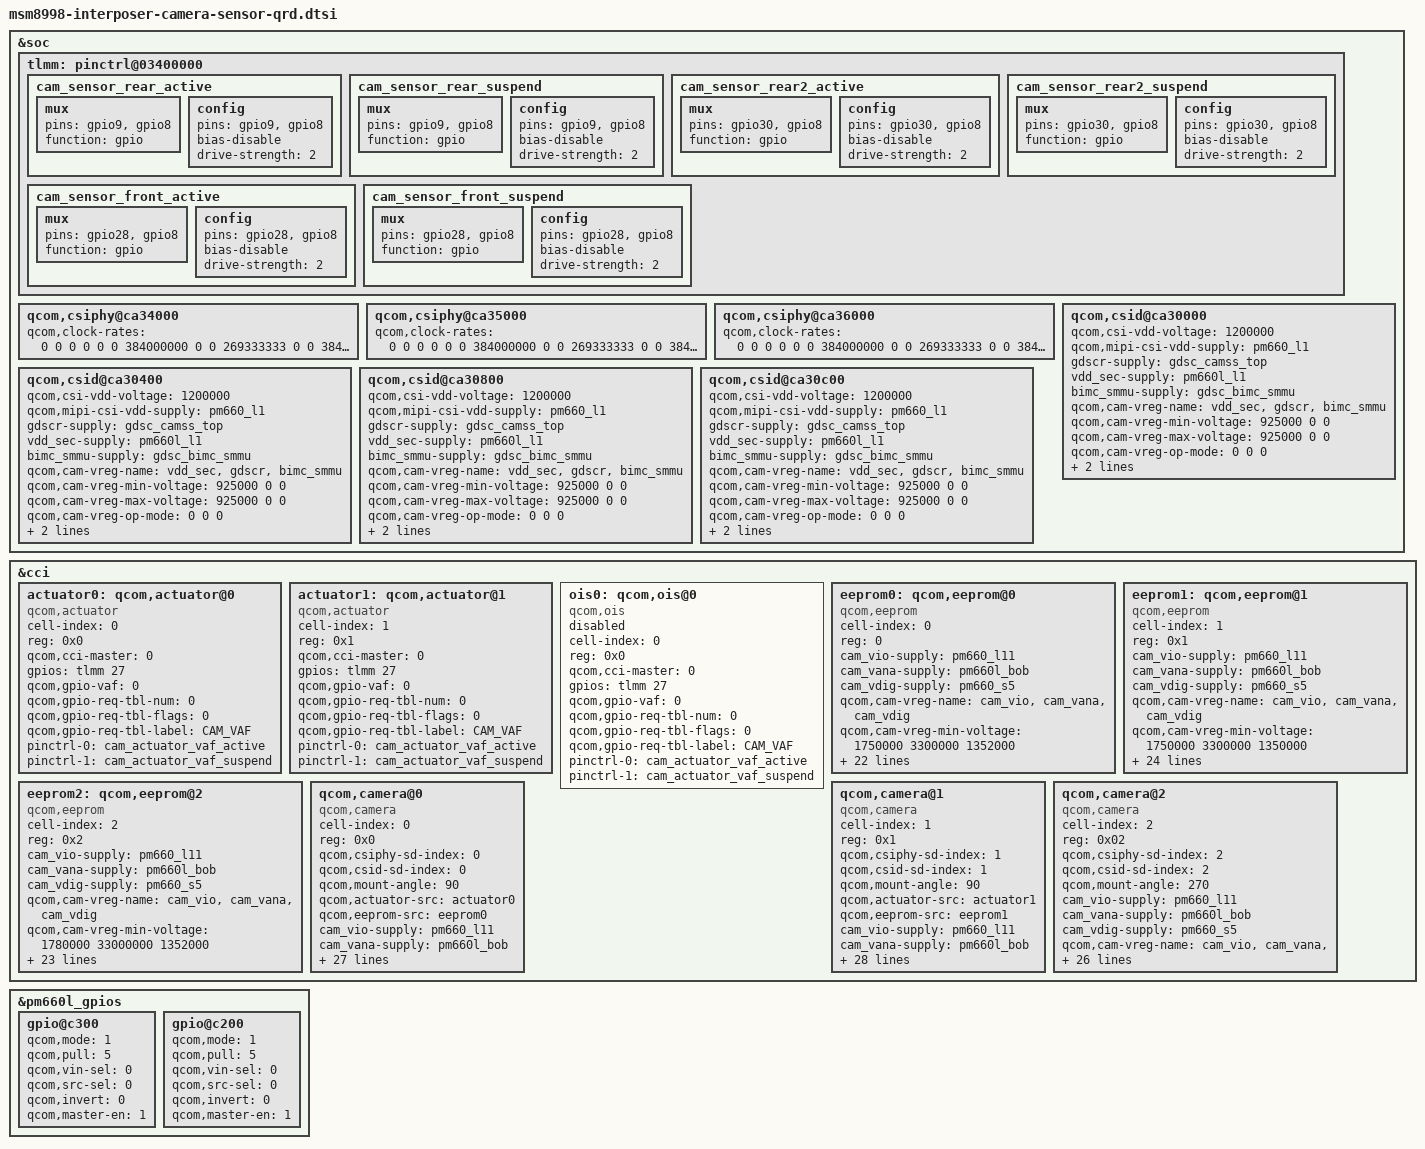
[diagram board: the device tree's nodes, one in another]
/*
 * Copyright (c) 2016-2017, The Linux Foundation. All rights reserved.
 *
 * This program is free software; you can redistribute it and/or modify
 * it under the terms of the GNU General Public License version 2 and
 * only version 2 as published by the Free Software Foundation.
 *
 * This program is distributed in the hope that it will be useful,
 * but WITHOUT ANY WARRANTY; without even the implied warranty of
 * MERCHANTABILITY or FITNESS FOR A PARTICULAR PURPOSE.  See the
 * GNU General Public License for more details.
 */

&soc {
	tlmm: pinctrl@03400000 {
		cam_sensor_rear_active: cam_sensor_rear_active {
			/* RESET, STANDBY */
			mux {
				pins = "gpio9", "gpio8";
				function = "gpio";
			};

			config {
				pins = "gpio9", "gpio8";
				bias-disable; /* No PULL */
				drive-strength = <2>; /* 2 MA */
			};
		};

		cam_sensor_rear_suspend: cam_sensor_rear_suspend {
			/* RESET, STANDBY */
			mux {
				pins = "gpio9", "gpio8";
				function = "gpio";
			};

			config {
				pins = "gpio9", "gpio8";
				bias-disable; /* No PULL */
				drive-strength = <2>; /* 2 MA */
			};
		};

		cam_sensor_rear2_active: cam_sensor_rear2_active {
			/* RESET, STANDBY */
			mux {
				pins = "gpio30", "gpio8";
				function = "gpio";
			};

			config {
				pins = "gpio30", "gpio8";
				bias-disable; /* No PULL */
				drive-strength = <2>; /* 2 MA */
			};
		};

		cam_sensor_rear2_suspend: cam_sensor_rear2_suspend {
			/* RESET, STANDBY */
			mux {
				pins = "gpio30", "gpio8";
				function = "gpio";
			};

			config {
				pins = "gpio30", "gpio8";
				bias-disable; /* No PULL */
				drive-strength = <2>; /* 2 MA */
			};
		};

		cam_sensor_front_active: cam_sensor_front_active {
			/* RESET */
			mux {
				pins = "gpio28","gpio8";
				function = "gpio";
			};

			config {
				pins = "gpio28","gpio8";
				bias-disable; /* No PULL */
				drive-strength = <2>; /* 2 MA */
			};
		};
		cam_sensor_front_suspend: cam_sensor_front_suspend {
			/* RESET */
			mux {
				pins = "gpio28","gpio8";
				function = "gpio";
			};

			config {
				pins = "gpio28","gpio8";
				bias-disable; /* No PULL */
				drive-strength = <2>; /* 2 MA */
			};
		};

	};

	qcom,csiphy@ca34000 {
		qcom,clock-rates = <0 0 0 0 0 0 384000000 0 0 269333333 0
			0 384000000 0>;
	};

	qcom,csiphy@ca35000 {
		qcom,clock-rates = <0 0 0 0 0 0 384000000 0 0 269333333 0
			0 384000000 0>;
	};

	qcom,csiphy@ca36000 {
		qcom,clock-rates = <0 0 0 0 0 0 384000000 0 0 269333333 0
			0 384000000 0>;
	};

	qcom,csid@ca30000  {
		qcom,csi-vdd-voltage = <1200000>;
		qcom,mipi-csi-vdd-supply = <&pm660_l1>;
		gdscr-supply = <&gdsc_camss_top>;
		vdd_sec-supply = <&pm660l_l1>;
		bimc_smmu-supply = <&gdsc_bimc_smmu>;
		qcom,cam-vreg-name = "vdd_sec", "gdscr", "bimc_smmu";
		qcom,cam-vreg-min-voltage = <925000 0 0>;
		qcom,cam-vreg-max-voltage = <925000 0 0>;
		qcom,cam-vreg-op-mode = <0 0 0>;
		qcom,clock-rates = <0 0 0 0 0 0 0 384000000 384000000
			0 0 0 0 0>;
	};

	qcom,csid@ca30400 {
		qcom,csi-vdd-voltage = <1200000>;
		qcom,mipi-csi-vdd-supply = <&pm660_l1>;
		gdscr-supply = <&gdsc_camss_top>;
		vdd_sec-supply = <&pm660l_l1>;
		bimc_smmu-supply = <&gdsc_bimc_smmu>;
		qcom,cam-vreg-name = "vdd_sec", "gdscr", "bimc_smmu";
		qcom,cam-vreg-min-voltage = <925000 0 0>;
		qcom,cam-vreg-max-voltage = <925000 0 0>;
		qcom,cam-vreg-op-mode = <0 0 0>;
		qcom,clock-rates = <0 0 0 0 0 0 0 384000000 384000000
			0 0 0 0 0>;
	};

	qcom,csid@ca30800 {
		qcom,csi-vdd-voltage = <1200000>;
		qcom,mipi-csi-vdd-supply = <&pm660_l1>;
		gdscr-supply = <&gdsc_camss_top>;
		vdd_sec-supply = <&pm660l_l1>;
		bimc_smmu-supply = <&gdsc_bimc_smmu>;
		qcom,cam-vreg-name = "vdd_sec", "gdscr", "bimc_smmu";
		qcom,cam-vreg-min-voltage = <925000 0 0>;
		qcom,cam-vreg-max-voltage = <925000 0 0>;
		qcom,cam-vreg-op-mode = <0 0 0>;
		qcom,clock-rates = <0 0 0 0 0 0 0 384000000 384000000
			0 0 0 0 0>;
	};

	qcom,csid@ca30c00 {
		qcom,csi-vdd-voltage = <1200000>;
		qcom,mipi-csi-vdd-supply = <&pm660_l1>;
		gdscr-supply = <&gdsc_camss_top>;
		vdd_sec-supply = <&pm660l_l1>;
		bimc_smmu-supply = <&gdsc_bimc_smmu>;
		qcom,cam-vreg-name = "vdd_sec", "gdscr", "bimc_smmu";
		qcom,cam-vreg-min-voltage = <925000 0 0>;
		qcom,cam-vreg-max-voltage = <925000 0 0>;
		qcom,cam-vreg-op-mode = <0 0 0>;
		qcom,clock-rates = <0 0 0 0 0 0 0 384000000 384000000
			0 0 0 0 0>;
	};
};

&soc {
	/delete-node/gpio-regulator@0;
};

&cci {
	/delete-node/qcom,camera@0;
	/delete-node/qcom,camera@1;
	/delete-node/qcom,camera@2;
	/delete-node/qcom,eeprom@0;
	/delete-node/qcom,eeprom@1;
	/delete-node/qcom,eeprom@2;
	/delete-node/qcom,actuator@0;
	/delete-node/qcom,actuator@1;
	/delete-node/qcom,ois@0;
};

&cci {
	actuator0: qcom,actuator@0 {
		cell-index = <0>;
		reg = <0x0>;
		compatible = "qcom,actuator";
		qcom,cci-master = <0>;
		gpios = <&tlmm 27 0>;
		qcom,gpio-vaf = <0>;
		qcom,gpio-req-tbl-num = <0>;
		qcom,gpio-req-tbl-flags = <0>;
		qcom,gpio-req-tbl-label = "CAM_VAF";
		pinctrl-names = "cam_default", "cam_suspend";
		pinctrl-0 = <&cam_actuator_vaf_active>;
		pinctrl-1 = <&cam_actuator_vaf_suspend>;
	};

	actuator1: qcom,actuator@1 {
		cell-index = <1>;
		reg = <0x1>;
		compatible = "qcom,actuator";
		qcom,cci-master = <0>;
		gpios = <&tlmm 27 0>;
		qcom,gpio-vaf = <0>;
		qcom,gpio-req-tbl-num = <0>;
		qcom,gpio-req-tbl-flags = <0>;
		qcom,gpio-req-tbl-label = "CAM_VAF";
		pinctrl-names = "cam_default", "cam_suspend";
		pinctrl-0 = <&cam_actuator_vaf_active>;
		pinctrl-1 = <&cam_actuator_vaf_suspend>;
	};

	ois0: qcom,ois@0 {
		cell-index = <0>;
		reg = <0x0>;
		compatible = "qcom,ois";
		qcom,cci-master = <0>;
		gpios = <&tlmm 27 0>;
		qcom,gpio-vaf = <0>;
		qcom,gpio-req-tbl-num = <0>;
		qcom,gpio-req-tbl-flags = <0>;
		qcom,gpio-req-tbl-label = "CAM_VAF";
		pinctrl-names = "cam_default", "cam_suspend";
		pinctrl-0 = <&cam_actuator_vaf_active>;
		pinctrl-1 = <&cam_actuator_vaf_suspend>;
		status = "disabled";
	};

	eeprom0: qcom,eeprom@0 {
		cell-index = <0>;
		reg = <0>;
		compatible = "qcom,eeprom";
		cam_vio-supply = <&pm660_l11>;
		cam_vana-supply = <&pm660l_bob>;
		cam_vdig-supply = <&pm660_s5>;
		qcom,cam-vreg-name = "cam_vio", "cam_vana", "cam_vdig";
		qcom,cam-vreg-min-voltage = <1750000 3300000 1352000>;
		qcom,cam-vreg-max-voltage = <1980000 3600000 1352000>;
		qcom,cam-vreg-op-mode = <105000 80000 105000>;
		qcom,gpio-no-mux = <0>;
		pinctrl-names = "cam_default", "cam_suspend";
		pinctrl-0 = <&cam_sensor_mclk0_active
				&cam_sensor_rear_active>;
		pinctrl-1 = <&cam_sensor_mclk0_suspend
				&cam_sensor_rear_suspend>;
		gpios = <&tlmm 13 0>,
			<&tlmm 9 0>,
			<&pm660l_gpios 4 0>,
			<&tlmm 8 0>;
		qcom,gpio-reset = <1>;
		qcom,gpio-vdig = <2>;
		qcom,gpio-vana = <3>;
		qcom,gpio-req-tbl-num = <0 1 2 3>;
		qcom,gpio-req-tbl-flags = <1 0 0 0>;
		qcom,gpio-req-tbl-label = "CAMIF_MCLK0",
					"CAM_RESET0",
					"CAM_VDIG",
					"CAM_VANA";
		qcom,sensor-position = <0>;
		qcom,sensor-mode = <0>;
		qcom,cci-master = <0>;
		status = "ok";
		clocks = <&clock_mmss clk_mclk0_clk_src>,
				<&clock_mmss clk_mmss_camss_mclk0_clk>;
		clock-names = "cam_src_clk", "cam_clk";
		qcom,clock-rates = <24000000 0>;
	};

	eeprom1: qcom,eeprom@1 {
		cell-index = <1>;
		reg = <0x1>;
		compatible = "qcom,eeprom";
		cam_vio-supply = <&pm660_l11>;
		cam_vana-supply = <&pm660l_bob>;
		cam_vdig-supply = <&pm660_s5>;
		qcom,cam-vreg-name = "cam_vio", "cam_vana", "cam_vdig";
		qcom,cam-vreg-min-voltage = <1750000 3300000 1350000>;
		qcom,cam-vreg-max-voltage = <1980000 3600000 1350000>;
		qcom,cam-vreg-op-mode = <105000 80000 105000>;
		qcom,gpio-no-mux = <0>;
		pinctrl-names = "cam_default", "cam_suspend";
		pinctrl-0 = <&cam_sensor_mclk2_active
				 &cam_sensor_rear2_active>;
		pinctrl-1 = <&cam_sensor_mclk2_suspend
				 &cam_sensor_rear2_suspend>;
		gpios = <&tlmm 15 0>,
			<&tlmm 30 0>,
			<&pm660l_gpios 4 0>,
			<&tlmm 8 0>,
			<&tlmm 27 0>;
		qcom,gpio-reset = <1>;
		qcom,gpio-vdig = <2>;
		qcom,gpio-vana = <3>;
		qcom,gpio-vaf = <4>;
		qcom,gpio-req-tbl-num = <0 1 2 3 4>;
		qcom,gpio-req-tbl-flags = <1 0 0 0 0>;
		qcom,gpio-req-tbl-label = "CAMIF_MCLK1",
					  "CAM_RESET1",
					  "CAM_VDIG1",
					  "CAM_VANA1",
					  "CAM_VAF";
		qcom,sensor-position = <0>;
		qcom,sensor-mode = <0>;
		qcom,cci-master = <0>;
		status = "ok";
		clocks = <&clock_mmss clk_mclk2_clk_src>,
			<&clock_mmss clk_mmss_camss_mclk2_clk>;
		clock-names = "cam_src_clk", "cam_clk";
		qcom,clock-rates = <24000000 0>;
	};

	eeprom2: qcom,eeprom@2 {
		cell-index = <2>;
		reg = <0x2>;
		compatible = "qcom,eeprom";
		cam_vio-supply = <&pm660_l11>;
		cam_vana-supply = <&pm660l_bob>;
		cam_vdig-supply = <&pm660_s5>;
		qcom,cam-vreg-name = "cam_vio", "cam_vana", "cam_vdig";
		qcom,cam-vreg-min-voltage = <1780000 33000000 1352000>;
		qcom,cam-vreg-max-voltage = <1950000 36000000 1352000>;
		qcom,cam-vreg-op-mode = <105000 80000 105000>;
		qcom,gpio-no-mux = <0>;
		pinctrl-names = "cam_default", "cam_suspend";
		pinctrl-0 = <&cam_sensor_mclk1_active
				 &cam_sensor_front_active>;
		pinctrl-1 = <&cam_sensor_mclk1_suspend
				 &cam_sensor_front_suspend>;
		gpios = <&tlmm 14 0>,
			<&tlmm 28 0>,
			<&pm660l_gpios 3 0>,
			<&tlmm 8 0>;
		qcom,gpio-reset = <1>;
		qcom,gpio-vdig = <2>;
		qcom,gpio-vana = <3>;
		qcom,gpio-req-tbl-num = <0 1 2 3>;
		qcom,gpio-req-tbl-flags = <1 0 0 0>;
		qcom,gpio-req-tbl-label = "CAMIF_MCLK2",
					"CAM_RESET2",
					"CAM_VDIG",
					"CAM_VANA";
		qcom,sensor-position = <1>;
		qcom,sensor-mode = <0>;
		qcom,cci-master = <1>;
		status = "ok";
		clocks = <&clock_mmss clk_mclk1_clk_src>,
			<&clock_mmss clk_mmss_camss_mclk1_clk>;
		clock-names = "cam_src_clk", "cam_clk";
		qcom,clock-rates = <24000000 0>;
	};

	qcom,camera@0 {
		cell-index = <0>;
		compatible = "qcom,camera";
		reg = <0x0>;
		qcom,csiphy-sd-index = <0>;
		qcom,csid-sd-index = <0>;
		qcom,mount-angle = <90>;
		qcom,actuator-src = <&actuator0>;
		/*qcom,ois-src = <&ois0>;*/
		qcom,eeprom-src = <&eeprom0>;
		cam_vio-supply = <&pm660_l11>;
		cam_vana-supply = <&pm660l_bob>;
		cam_vdig-supply = <&pm660_s5>;
		qcom,cam-vreg-name = "cam_vio", "cam_vana", "cam_vdig";
		qcom,cam-vreg-min-voltage = <1780000 3300000 1350000>;
		qcom,cam-vreg-max-voltage = <1950000 3600000 1350000>;
		qcom,cam-vreg-op-mode = <105000 80000 105000>;
		qcom,gpio-no-mux = <0>;
		pinctrl-names = "cam_default", "cam_suspend";
		pinctrl-0 = <&cam_sensor_mclk0_active
				 &cam_sensor_rear_active>;
		pinctrl-1 = <&cam_sensor_mclk0_suspend
				 &cam_sensor_rear_suspend>;
		gpios = <&tlmm 13 0>,
			<&tlmm 9 0>,
			<&pm660l_gpios 4 0>,
			<&tlmm 8 0>;
		qcom,gpio-reset = <1>;
		qcom,gpio-vdig = <2>;
		qcom,gpio-vana = <3>;
		qcom,gpio-req-tbl-num = <0 1 2 3>;
		qcom,gpio-req-tbl-flags = <1 0 0 0>;
		qcom,gpio-req-tbl-label = "CAMIF_MCLK2",
					"CAM_RESET0",
					"CAM_VDIG",
					"CAM_VANA";
		qcom,sensor-position = <0>;
		qcom,sensor-mode = <0>;
		qcom,cci-master = <0>;
		status = "ok";
		clocks = <&clock_mmss clk_mclk0_clk_src>,
				<&clock_mmss clk_mmss_camss_mclk0_clk>;
		clock-names = "cam_src_clk", "cam_clk";
		qcom,clock-rates = <24000000 0>;
	};

	qcom,camera@1 {
		cell-index = <1>;
		compatible = "qcom,camera";
		reg = <0x1>;
		qcom,csiphy-sd-index = <1>;
		qcom,csid-sd-index = <1>;
		qcom,mount-angle = <90>;
		qcom,actuator-src = <&actuator1>;
		qcom,eeprom-src = <&eeprom1>;
		cam_vio-supply = <&pm660_l11>;
		cam_vana-supply = <&pm660l_bob>;
		cam_vdig-supply = <&pm660_s5>;
		qcom,cam-vreg-name = "cam_vio", "cam_vana", "cam_vdig";
		qcom,cam-vreg-min-voltage = <1780000 3300000 1350000>;
		qcom,cam-vreg-max-voltage = <1950000 3600000 1350000>;
		qcom,cam-vreg-op-mode = <105000 80000 105000>;
		qcom,gpio-no-mux = <0>;
		pinctrl-names = "cam_default", "cam_suspend";
		pinctrl-0 = <&cam_sensor_mclk2_active
				 &cam_sensor_rear2_active>;
		pinctrl-1 = <&cam_sensor_mclk2_suspend
				 &cam_sensor_rear2_suspend>;
		gpios = <&tlmm 15 0>,
			<&tlmm 30 0>,
			<&pm660l_gpios 4 0>,
			<&tlmm 8 0>;
		qcom,gpio-reset = <1>;
		qcom,gpio-vdig = <2>;
		qcom,gpio-vana = <3>;
		qcom,gpio-req-tbl-num = <0 1 2 3>;
		qcom,gpio-req-tbl-flags = <1 0 0 0>;
		qcom,gpio-req-tbl-label = "CAMIF_MCLK1",
					  "CAM_RESET1",
					  "CAM_VDIG1",
					  "CAM_VANA1";
		qcom,sensor-position = <0>;
		qcom,sensor-mode = <0>;
		qcom,cci-master = <0>;
		status = "ok";
		clocks = <&clock_mmss clk_mclk2_clk_src>,
			<&clock_mmss clk_mmss_camss_mclk2_clk>;
		clock-names = "cam_src_clk", "cam_clk";
		qcom,clock-rates = <24000000 0>;
	};

	qcom,camera@2 {
		cell-index = <2>;
		compatible = "qcom,camera";
		reg = <0x02>;
		qcom,csiphy-sd-index = <2>;
		qcom,csid-sd-index = <2>;
		qcom,mount-angle = <270>;
		/*qcom,eeprom-src = <&eeprom2>;*/
		cam_vio-supply = <&pm660_l11>;
		cam_vana-supply = <&pm660l_bob>;
		cam_vdig-supply = <&pm660_s5>;
		qcom,cam-vreg-name = "cam_vio", "cam_vana", "cam_vdig";
		qcom,cam-vreg-min-voltage = <1780000 3300000 1350000>;
		qcom,cam-vreg-max-voltage = <1950000 3600000 1350000>;
		qcom,cam-vreg-op-mode = <105000 80000 105000>;
		qcom,gpio-no-mux = <0>;
		pinctrl-names = "cam_default", "cam_suspend";
		pinctrl-0 = <&cam_sensor_mclk1_active
				 &cam_sensor_front_active>;
		pinctrl-1 = <&cam_sensor_mclk1_suspend
				 &cam_sensor_front_suspend>;
		gpios = <&tlmm 14 0>,
			<&tlmm 28 0>,
			<&pm660l_gpios 3 0>,
			<&tlmm 8 0>;
		qcom,gpio-reset = <1>;
		qcom,gpio-vdig = <2>;
		qcom,gpio-vana = <3>;
		qcom,gpio-req-tbl-num = <0 1 2 3>;
		qcom,gpio-req-tbl-flags = <1 0 0 0>;
		qcom,gpio-req-tbl-label = "CAMIF_MCLK2",
					"CAM_RESET2",
					"CAM_VDIG",
					"CAM_VANA";
		qcom,sensor-position = <1>;
		qcom,sensor-mode = <0>;
		qcom,cci-master = <1>;
		status = "ok";
		clocks = <&clock_mmss clk_mclk1_clk_src>,
			<&clock_mmss clk_mmss_camss_mclk1_clk>;
		clock-names = "cam_src_clk", "cam_clk";
		qcom,clock-rates = <24000000 0>;
	};
};

&pm660l_gpios {
	gpio@c300 { /* GPIO4 -CAMERA SENSOR 0 VDIG*/
		qcom,mode = <1>;                /* Output */
		qcom,pull = <5>;                /* No Pull */
		qcom,vin-sel = <0>;             /* VIN1 GPIO_LV */
		qcom,src-sel = <0>;             /* GPIO */
		qcom,invert = <0>;              /* Invert */
		qcom,master-en = <1>;           /* Enable GPIO */
		status = "ok";
	};

	gpio@c200 { /* GPIO3 -CAMERA SENSOR 2 VDIG*/
		qcom,mode = <1>;                /* Output */
		qcom,pull = <5>;                /* No Pull */
		qcom,vin-sel = <0>;             /* VIN1 GPIO_LV */
		qcom,src-sel = <0>;             /* GPIO */
		qcom,invert = <0>;              /* Invert */
		qcom,master-en = <1>;           /* Enable GPIO */
		status = "ok";
	};
};
